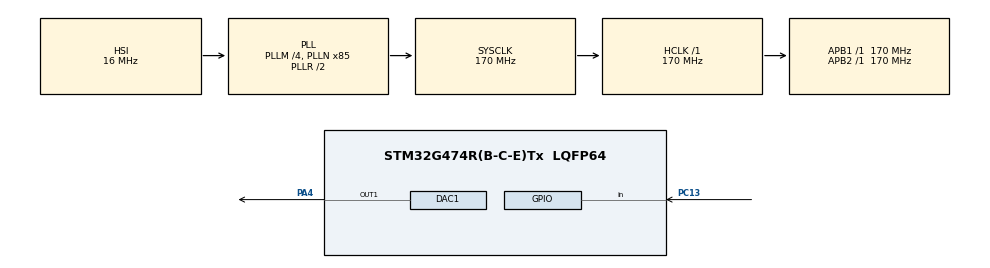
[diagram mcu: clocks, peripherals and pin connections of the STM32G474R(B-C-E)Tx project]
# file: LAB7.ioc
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Mcu.Family=STM32G4
Mcu.Name=STM32G474R(B-C-E)Tx
Mcu.Package=LQFP64
NVIC.PriorityGroup=NVIC_PRIORITYGROUP_4
NVIC.TIM6_DAC_IRQn=true\:0\:0\:false\:false\:true\:true\:true\:true
PA13.GPIO_Label=T_SWDIO
PA13.Signal=SYS_JTMS-SWDIO
PA14.GPIO_Label=T_SWCLK
PA14.Signal=SYS_JTCK-SWCLK
PA2.GPIO_Label=LPUART1_TX [STLINKV3E_VCP_RX]
PA2.Signal=LPUART1_TX
PA3.GPIO_Label=LPUART1_RX [STLINKV3E_VCP_TX]
PA3.Signal=LPUART1_RX
PA4.Signal=COMP_DAC11_group
PB3.GPIO_Label=T_SWO
PB3.Signal=SYS_JTDO-SWO
PC13.Signal=GPIO_Input
PC14-OSC32_IN.GPIO_Label=RCC_OSC32_IN
PC14-OSC32_IN.Signal=RCC_OSC32_IN
PC15-OSC32_OUT.GPIO_Label=RCC_OSC32_OUT
PC15-OSC32_OUT.Signal=RCC_OSC32_OUT
PF0-OSC_IN.GPIO_Label=RCC_OSC_IN
PF0-OSC_IN.Signal=RCC_OSC_IN
PF1-OSC_OUT.GPIO_Label=RCC_OSC_OUT
PF1-OSC_OUT.Signal=RCC_OSC_OUT
ProjectManager.HeapSize=0x200
ProjectManager.StackSize=0x400
ProjectManager.TargetToolchain=STM32CubeIDE
RCC.ADC12Freq_Value=170000000
RCC.ADC345Freq_Value=170000000
RCC.AHBFreq_Value=170000000
RCC.APB1Freq_Value=170000000
RCC.APB1TimFreq_Value=170000000
RCC.APB2Freq_Value=170000000
RCC.APB2TimFreq_Value=170000000
RCC.CortexFreq_Value=170000000
RCC.EXTERNAL_CLOCK_VALUE=12288000
RCC.HCLKFreq_Value=170000000
RCC.HSE_VALUE=24000000
RCC.HSI48_VALUE=48000000
RCC.HSI_VALUE=16000000
RCC.LSE_VALUE=32768
RCC.PLLM=RCC_PLLM_DIV4
RCC.PLLN=85
RCC.RTCClockSelection=RCC_RTCCLKSOURCE_LSE
RCC.SYSCLKFreq_VALUE=170000000
RCC.SYSCLKSource=RCC_SYSCLKSOURCE_PLLCLK
RCC.USBFreq_Value=170000000
RCC.VCOOutputFreq_Value=340000000
SH.COMP_DAC11_group.0=DAC1_OUT1,DAC_OUT1
TIM6.PeriodNoDither=199
TIM6.Prescaler=169
VP_SYS_VS_DBSignals.Mode=DisableDeadBatterySignals
VP_TIM6_VS_ClockSourceINT.Mode=Enable_Timer
board=NUCLEO-G474RE

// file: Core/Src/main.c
/* USER CODE BEGIN Header */
/**
  ******************************************************************************
  * @file           : main.c
  * @brief          : Main program body
  ******************************************************************************
  * @attention
  *
  * Copyright (c) 2026 STMicroelectronics.
  * All rights reserved.
  *
  * This software is licensed under terms that can be found in the LICENSE file
  * in the root directory of this software component.
  * If no LICENSE file comes with this software, it is provided AS-IS.
  *
  ******************************************************************************
  */
/* USER CODE END Header */
#include "main.h"

/* USER CODE BEGIN Includes */
#include <math.h>
/* USER CODE END Includes */

DAC_HandleTypeDef hdac1;

TIM_HandleTypeDef htim6;

/* USER CODE BEGIN PV */
uint8_t wave_mode = 0;
uint8_t index_wave = 0;
uint32_t last_press = 0;

uint16_t sine_table[100];
/* USER CODE END PV */

void SystemClock_Config(void);
static void MX_GPIO_Init(void);
static void MX_DAC1_Init(void);
static void MX_TIM6_Init(void);

int main(void)
{

  /* MCU Configuration--------------------------------------------------------*/

  /* Reset of all peripherals, Initializes the Flash interface and the Systick. */
  HAL_Init();

  /* Configure the system clock */
  SystemClock_Config();

  /* Initialize all configured peripherals */
  MX_GPIO_Init();
  MX_DAC1_Init();
  MX_TIM6_Init();
  /* USER CODE BEGIN 2 */
  for (int i = 0; i < 100; i++)
  {
      sine_table[i] = (uint16_t)(
          2048 + 1800 * sinf(2.0f * 3.1415926f * i / 100.0f)
      );
  }

  HAL_DAC_Start(&hdac1, DAC_CHANNEL_1);
  HAL_TIM_Base_Start_IT(&htim6);

  /* USER CODE END 2 */

  /* Infinite loop */
  while (1)
  {

    /* USER CODE BEGIN 3 */
	  while (1)
	  {
	      if (HAL_GPIO_ReadPin(GPIOC, GPIO_PIN_13) == GPIO_PIN_SET)
	      {
	          if (HAL_GetTick() - last_press > 200)
	          {
	              wave_mode = (wave_mode + 1) % 3;
	              index_wave = 0;
	              last_press = HAL_GetTick();
	          }

	          while (HAL_GPIO_ReadPin(GPIOC, GPIO_PIN_13) == GPIO_PIN_SET)
	          {
	              // 等待放開按鈕
	          }
	      }
	  }
  }
  /* USER CODE END 3 */
}

void SystemClock_Config(void)
{
  RCC_OscInitTypeDef RCC_OscInitStruct = {0};
  RCC_ClkInitTypeDef RCC_ClkInitStruct = {0};

  /** Configure the main internal regulator output voltage
  */
  HAL_PWREx_ControlVoltageScaling(PWR_REGULATOR_VOLTAGE_SCALE1_BOOST);

  /** Initializes the RCC Oscillators according to the specified parameters
  * in the RCC_OscInitTypeDef structure.
  */
  RCC_OscInitStruct.OscillatorType = RCC_OSCILLATORTYPE_HSI;
  RCC_OscInitStruct.HSIState = RCC_HSI_ON;
  RCC_OscInitStruct.HSICalibrationValue = RCC_HSICALIBRATION_DEFAULT;
  RCC_OscInitStruct.PLL.PLLState = RCC_PLL_ON;
  RCC_OscInitStruct.PLL.PLLSource = RCC_PLLSOURCE_HSI;
  RCC_OscInitStruct.PLL.PLLM = RCC_PLLM_DIV4;
  RCC_OscInitStruct.PLL.PLLN = 85;
  RCC_OscInitStruct.PLL.PLLP = RCC_PLLP_DIV2;
  RCC_OscInitStruct.PLL.PLLQ = RCC_PLLQ_DIV2;
  RCC_OscInitStruct.PLL.PLLR = RCC_PLLR_DIV2;
  if (HAL_RCC_OscConfig(&RCC_OscInitStruct) != HAL_OK)
  {
    Error_Handler();
  }

  /** Initializes the CPU, AHB and APB buses clocks
  */
  RCC_ClkInitStruct.ClockType = RCC_CLOCKTYPE_HCLK|RCC_CLOCKTYPE_SYSCLK
                              |RCC_CLOCKTYPE_PCLK1|RCC_CLOCKTYPE_PCLK2;
  RCC_ClkInitStruct.SYSCLKSource = RCC_SYSCLKSOURCE_PLLCLK;
  RCC_ClkInitStruct.AHBCLKDivider = RCC_SYSCLK_DIV1;
  RCC_ClkInitStruct.APB1CLKDivider = RCC_HCLK_DIV1;
  RCC_ClkInitStruct.APB2CLKDivider = RCC_HCLK_DIV1;

  if (HAL_RCC_ClockConfig(&RCC_ClkInitStruct, FLASH_LATENCY_4) != HAL_OK)
  {
    Error_Handler();
  }
}

static void MX_DAC1_Init(void)
{

  DAC_ChannelConfTypeDef sConfig = {0};

  /** DAC Initialization
  */
  hdac1.Instance = DAC1;
  if (HAL_DAC_Init(&hdac1) != HAL_OK)
  {
    Error_Handler();
  }

  /** DAC channel OUT1 config
  */
  sConfig.DAC_HighFrequency = DAC_HIGH_FREQUENCY_INTERFACE_MODE_AUTOMATIC;
  sConfig.DAC_DMADoubleDataMode = DISABLE;
  sConfig.DAC_SignedFormat = DISABLE;
  sConfig.DAC_SampleAndHold = DAC_SAMPLEANDHOLD_DISABLE;
  sConfig.DAC_Trigger = DAC_TRIGGER_NONE;
  sConfig.DAC_Trigger2 = DAC_TRIGGER_NONE;
  sConfig.DAC_OutputBuffer = DAC_OUTPUTBUFFER_ENABLE;
  sConfig.DAC_ConnectOnChipPeripheral = DAC_CHIPCONNECT_EXTERNAL;
  sConfig.DAC_UserTrimming = DAC_TRIMMING_FACTORY;
  if (HAL_DAC_ConfigChannel(&hdac1, &sConfig, DAC_CHANNEL_1) != HAL_OK)
  {
    Error_Handler();
  }

}

static void MX_TIM6_Init(void)
{

  TIM_MasterConfigTypeDef sMasterConfig = {0};

  htim6.Instance = TIM6;
  htim6.Init.Prescaler = 169;
  htim6.Init.CounterMode = TIM_COUNTERMODE_UP;
  htim6.Init.Period = 199;
  htim6.Init.AutoReloadPreload = TIM_AUTORELOAD_PRELOAD_DISABLE;
  if (HAL_TIM_Base_Init(&htim6) != HAL_OK)
  {
    Error_Handler();
  }
  sMasterConfig.MasterOutputTrigger = TIM_TRGO_RESET;
  sMasterConfig.MasterSlaveMode = TIM_MASTERSLAVEMODE_DISABLE;
  if (HAL_TIMEx_MasterConfigSynchronization(&htim6, &sMasterConfig) != HAL_OK)
  {
    Error_Handler();
  }

}

static void MX_GPIO_Init(void)
{
  GPIO_InitTypeDef GPIO_InitStruct = {0};

  /* GPIO Ports Clock Enable */
  __HAL_RCC_GPIOC_CLK_ENABLE();
  __HAL_RCC_GPIOF_CLK_ENABLE();
  __HAL_RCC_GPIOA_CLK_ENABLE();
  __HAL_RCC_GPIOB_CLK_ENABLE();

  /*Configure GPIO pin : PC13 */
  GPIO_InitStruct.Pin = GPIO_PIN_13;
  GPIO_InitStruct.Mode = GPIO_MODE_INPUT;
  GPIO_InitStruct.Pull = GPIO_NOPULL;
  HAL_GPIO_Init(GPIOC, &GPIO_InitStruct);

  /*Configure GPIO pins : LPUART1_TX_Pin LPUART1_RX_Pin */
  GPIO_InitStruct.Pin = LPUART1_TX_Pin|LPUART1_RX_Pin;
  GPIO_InitStruct.Mode = GPIO_MODE_AF_PP;
  GPIO_InitStruct.Pull = GPIO_NOPULL;
  GPIO_InitStruct.Speed = GPIO_SPEED_FREQ_LOW;
  GPIO_InitStruct.Alternate = GPIO_AF12_LPUART1;
  HAL_GPIO_Init(GPIOA, &GPIO_InitStruct);

}

/* USER CODE BEGIN 4 */
void HAL_TIM_PeriodElapsedCallback(TIM_HandleTypeDef *htim)
{
    if (htim->Instance == TIM6)
    {
        uint16_t value = 2048;

        if (wave_mode == 0)
        {
            // 正弦波：使用原本建立的100點查表
            value = sine_table[index_wave];
        }
        else if (wave_mode == 1)
        {
            // 三角波
            if (index_wave < 25)
                value = 2048 + 72 * index_wave;
            else if (index_wave < 75)
                value = 3848 - 72 * (index_wave - 25);
            else
                value = 248 + 72 * (index_wave - 75);
        }
        else
        {
            // 方波
            if (index_wave < 50)
                value = 3848;
            else
                value = 248;
        }

        HAL_DAC_SetValue(&hdac1,
                         DAC_CHANNEL_1,
                         DAC_ALIGN_12B_R,
                         value);

        index_wave++;

        if (index_wave >= 100)
            index_wave = 0;
    }
}
/* USER CODE END 4 */

void Error_Handler(void)
{
  __disable_irq();
  while (1)
  {
  }
}
